# PIC32CM5112SG00100 register map
Vendor: Microchip Technology; Series: PIC32CMSG00; File version: 0
CPU: CM23 r0p0, little endian, MPU, no FPU, 2 interrupt priority bits, 141 interrupts, 13 SAU regions
Registers are 32-bit, read-write, reset 0x0 unless marked. A register's access mark holds for its fields unless they carry their own. Offsets are from the block's base; [hi:lo] are bit positions; {n}, {i} and the like mark numbered series; 'fields as' and 'values as' point back to an identical list.

## DSU — Polaris Device Services Unit Macro DOS
Base 0x44000000
0x00 CTRLA — Control A REGISTER
  [2] PRIV — Privileged Access Only for APB Interface
    0=Internal Address Space registers accessible in privileged and unprivileged modes. Test functions generate unprivileged requests.; 1=Internal Address Space registers only accessible in privileged mode. Test functions generate privileged requests.
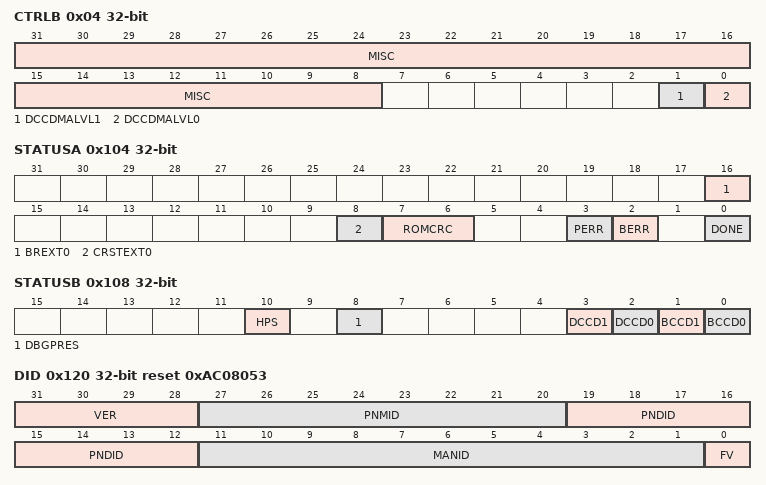
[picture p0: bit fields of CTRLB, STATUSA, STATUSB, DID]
0x04 CTRLB — Control B REGISTER
  [31:8] MISC — Device Specific Configuration Register
  [1] DCCDMALVL1 — DMA Trigger n Level
    0=EMPTY (Trigger n rises when DCCn is read and falls when it is written); 1=FULL (Trigger n rises when DCCn is written and falls when it is read)
  [0] DCCDMALVL0 — DMA Trigger n Level
    values as DCCDMALVL1
0x100 CTRLC — Control C REGISTER
  [0] DBGRW0 — CPUn Debug R/W
    0=Allow debugger accesses through CPUn to carry the debug attribute (i.e debugger reads are non-destructive); 1=Debugger accesses through CPUn do not carry the debug attribute (i.e debugger reads are destructive)
0x104 STATUSA write-1-clears
  [16] BREXT0 — BootRom 0 Phase Extension Status
    0=Boot ROM Phase Extension released for CPUx; 1=Boot ROM Phase Extension for CPUx. Set on Cold-Plugging detection.
  [8] CRSTEXT0 — CPUx Reset Extension Status
    0=CPUx released from reset extension; 1=CPUx held in reset extension. Set on Cold-Plugging detection.
  [7:6] ROMCRC — Boot ROM CRC Self-Check Status
    0=CRC is in progress; 1=CRC completed but failed indicating possible issue with the ROM content. System held in lockup state.; 2=CRC completed and passed; 3=CRC never executed because user disabled CRC check through fuse settings
  [3] PERR — Protection Error Status
    0=No protection error detected; 1=Invalid command written to TCTRL.CMD, partial write to the upper or lower bytes of TCTRL.CMD, or invalid key written to SAFEDOOR
  [2] BERR — Bus Error Status
    0=No bus error detected; 1=Bus error incurred while performing the DSU command
  [0] DONE — Done Status
    0=DSU is executing a command or idle; 1=TCTRL.CMD command completed
0x108 STATUSB ro
  [10] HPS — Hot-Plugging Status
    0=Hot-Plugging inactive; 1=Hot-Plugging active
  [8] DBGPRES — Debugger Present Status
    0=No debugger detected; 1=Debugger probe detected
  [3] DCCD1 — Debug Communication Channel 1 Dirty
    0=DCCDx.DATA register was read from; 1=DCCDx.DATA register was written to
  [2] DCCD0 — Debug Communication Channel 0 Dirty
    values as DCCD1
  [1] BCCD1 — Boot ROM Communication Channel 1 Dirty
    0=BCCDx.DATA register was read from; 1=BCCDx.DATA register was written to
  [0] BCCD0 — Boot ROM Communication Channel 0 Dirty
    values as BCCD1
{0x110+4i} BCC[{i}] (i=0..1) — Boot ROM Channel n REGISTER
  [31:0] DATA
{0x118+4i} DCC[{i}] (i=0..1) — Debug Communication Channel n REGISTER
  [31:0] DATA
0x120 DID reset 0xAC08053 — Device Identification Register
  [31:28] VER — Version Code
  [27:20] PNMID — Part Number Mask ID
  [19:12] PNDID — Part Number Device ID
  [11:1] MANID — JEDEC Manufacture ID
  [0] FV — Fixed Value of 1
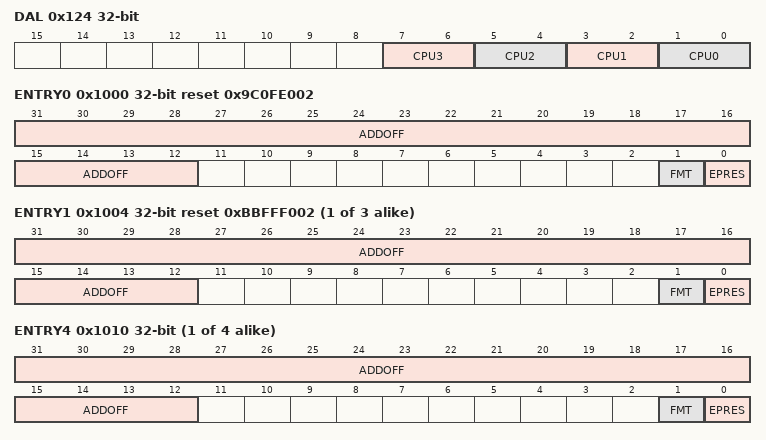
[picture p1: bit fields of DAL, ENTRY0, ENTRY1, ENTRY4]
0x124 DAL ro — Debugger Access Level REGISTER
  [7:6] CPU3 — CPU n Debugger Access Level
    0=SECURED (Debugger access is disabled); 1=NS_DEBUG (Debugger can access only non-secure regions); 2=FULL_DEBUG (Debugger has full access to debug CPUn); 3=UNIMPLEMENTED (Unimplemented CPU)
  [5:4] CPU2 — CPU n Debugger Access Level
    values as CPU3
  [3:2] CPU1 — CPU n Debugger Access Level
    values as CPU3
  [1:0] CPU0 — CPU 0 Debugger Access Level
    0=SECURED (Debugger targeting CPU0 domain can only access the DSU external address space otherwise debugger access is disabled); 1=NS_DEBUG (Debugger can access only non-secure regions); 2=FULL_DEBUG (Debugger can access secure and non-secure regions)
0x1000 ENTRY0 ro reset 0x9C0FE002 — CoreSight ROM Table Entry N Register
  [31:12] ADDOFF — CoreSight ROM Table Address Offset
  [1] FMT — CoreSight Rom Table Format
    0=8-bit format; 1=32-bit format
  [0] EPRES — CoreSight Entry Present
    0=Entry not present; 1=Entry present
{0x1000+4i} ENTRY{i} ro reset 0xBBFFF002 (i=1..3) — CoreSight ROM Table Entry N Register
  fields as ENTRY0
{0x1000+4i} ENTRY{i} ro (i=4..7) — CoreSight ROM Table Entry {i} Register
  fields as ENTRY0
0x1FCC MEMTYPE ro — CoreSight ROM Table Memory Type Register
  [0] SYSMEM — CoreSight System Memory Present
    0=System memory not present on bus. This is a dedicated debug bus.; 1=System memory is also present on this bus
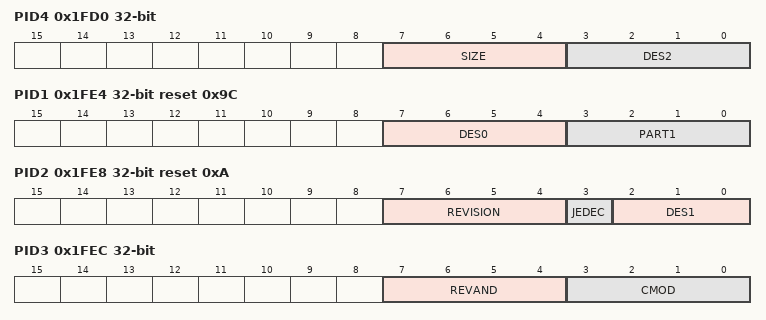
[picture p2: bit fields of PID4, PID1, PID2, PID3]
0x1FD0 PID4 ro — CoreSight Peripheral Identification 4 Register
  [7:4] SIZE — CoreSight Size
  [3:0] DES2 — CoreSight JEP106 Continuation Code
{0x1FC0+4i} PID{i} ro (i=5..7) — CoreSight Peripheral Identification {i} Register
  [7:0] RES0 — CoreSight Reserved Field
0x1FE0 PID0 ro reset 0xD0 — CoreSight Peripheral Identification 0 Register
  [7:0] PART0 — CoreSight Part Number Bits[7:0]
0x1FE4 PID1 ro reset 0x9C — CoreSight Peripheral Identification 1 Register
  [7:4] DES0 — CoreSight JEP106 Identification Code Bits [3:0]
  [3:0] PART1 — CoreSight Part Number Bits[11:8]
0x1FE8 PID2 ro reset 0xA — CoreSight Peripheral Identification 2 Register
  [7:4] REVISION — CoreSight Revision
  [3] JEDEC — CoreSight JEDEC Assignment
  [2:0] DES1 — CoreSight JEP106 Identification Code Bits [6:4]
0x1FEC PID3 ro — CoreSight Peripheral Identification 3 Register
  [7:4] REVAND — CoreSight REVAND
  [3:0] CMOD — CoreSight Custom Modifier 0
0x1FF0 CID0 ro reset 0xD — CoreSight Component Identification 0 Register
  [7:0] PRMBL0 — CoreSight Preamble 0
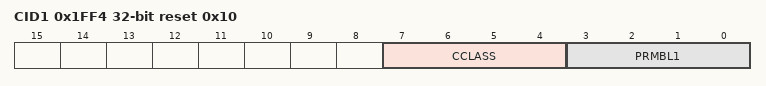
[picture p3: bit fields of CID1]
0x1FF4 CID1 ro reset 0x10 — CoreSight Component Identification 1 Register
  [7:4] CCLASS — CoreSight Component Class
  [3:0] PRMBL1 — CoreSight Preamble 1
0x1FF8 CID2 ro reset 0x5 — CoreSight Component Identification 2 Register
  [7:0] PRMBL2 — CoreSight Preamble 2
0x1FFC CID3 ro reset 0xB1 — CoreSight Component Identification 3 Register
  [7:0] PRMBL3 — CoreSight Preamble 3
